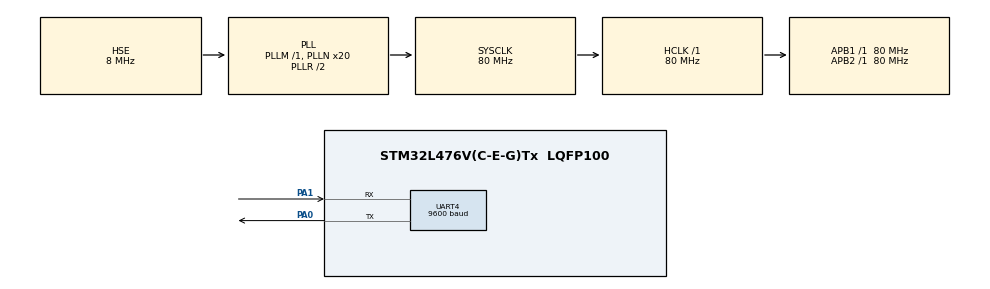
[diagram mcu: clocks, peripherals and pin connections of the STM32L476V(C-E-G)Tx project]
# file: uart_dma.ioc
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Dma.Request0=UART4_RX
Dma.Request1=UART4_TX
Dma.UART4_RX.0.Direction=DMA_PERIPH_TO_MEMORY
Dma.UART4_RX.0.Instance=DMA2_Channel5
Dma.UART4_RX.0.MemDataAlignment=DMA_MDATAALIGN_BYTE
Dma.UART4_RX.0.MemInc=DMA_MINC_ENABLE
Dma.UART4_RX.0.Mode=DMA_NORMAL
Dma.UART4_RX.0.PeriphDataAlignment=DMA_PDATAALIGN_BYTE
Dma.UART4_RX.0.PeriphInc=DMA_PINC_DISABLE
Dma.UART4_RX.0.Priority=DMA_PRIORITY_HIGH
Dma.UART4_TX.1.Direction=DMA_MEMORY_TO_PERIPH
Dma.UART4_TX.1.Instance=DMA2_Channel3
Dma.UART4_TX.1.MemDataAlignment=DMA_MDATAALIGN_BYTE
Dma.UART4_TX.1.MemInc=DMA_MINC_ENABLE
Dma.UART4_TX.1.Mode=DMA_NORMAL
Dma.UART4_TX.1.PeriphDataAlignment=DMA_PDATAALIGN_BYTE
Dma.UART4_TX.1.PeriphInc=DMA_PINC_DISABLE
Dma.UART4_TX.1.Priority=DMA_PRIORITY_LOW
Mcu.Family=STM32L4
Mcu.Name=STM32L476V(C-E-G)Tx
Mcu.Package=LQFP100
NVIC.DMA2_Channel3_IRQn=true\:0\:0\:false\:false\:true\:false\:true
NVIC.DMA2_Channel5_IRQn=true\:0\:0\:false\:false\:true\:false\:true
NVIC.PriorityGroup=NVIC_PRIORITYGROUP_4
NVIC.UART4_IRQn=true\:0\:0\:false\:false\:true\:true\:true
PA0.Mode=Asynchronous
PA0.Signal=UART4_TX
PA1.Mode=Asynchronous
PA1.Signal=UART4_RX
PH0-OSC_IN\ (PH0).Mode=HSE-External-Oscillator
PH0-OSC_IN\ (PH0).Signal=RCC_OSC_IN
PH1-OSC_OUT\ (PH1).Mode=HSE-External-Oscillator
PH1-OSC_OUT\ (PH1).Signal=RCC_OSC_OUT
ProjectManager.HeapSize=0x200
ProjectManager.StackSize=0x400
ProjectManager.TargetToolchain=EWARM V8
RCC.ADCFreq_Value=32000000
RCC.AHBFreq_Value=80000000
RCC.APB1Freq_Value=80000000
RCC.APB1TimFreq_Value=80000000
RCC.APB2Freq_Value=80000000
RCC.APB2TimFreq_Value=80000000
RCC.CortexFreq_Value=80000000
RCC.HCLKFreq_Value=80000000
RCC.HSE_VALUE=8000000
RCC.HSI_VALUE=16000000
RCC.LSE_VALUE=32768
RCC.MSI_VALUE=4000000
RCC.PLLN=20
RCC.PLLSourceVirtual=RCC_PLLSOURCE_HSE
RCC.SYSCLKFreq_VALUE=80000000
RCC.SYSCLKSource=RCC_SYSCLKSOURCE_PLLCLK
RCC.USBFreq_Value=32000000
RCC.VCOOutputFreq_Value=160000000
UART4.BaudRate=9600
board=custom

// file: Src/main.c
/* USER CODE BEGIN Header */
/**
  ******************************************************************************
  * @file           : main.c
  * @brief          : Main program body
  ******************************************************************************
  * @attention
  *
  * <h2><center>&copy; Copyright (c) 2019 STMicroelectronics.
  * All rights reserved.</center></h2>
  *
  * This software component is licensed by ST under BSD 3-Clause license,
  * the "License"; You may not use this file except in compliance with the
  * License. You may obtain a copy of the License at:
  *                        opensource.org/licenses/BSD-3-Clause
  *
  ******************************************************************************
  */
/* USER CODE END Header */

#include "main.h"

UART_HandleTypeDef huart4;
DMA_HandleTypeDef hdma_uart4_rx;
DMA_HandleTypeDef hdma_uart4_tx;

/* USER CODE BEGIN PV */
uint8_t rx_buff[8];
/* USER CODE END PV */

void SystemClock_Config(void);
static void MX_GPIO_Init(void);
static void MX_DMA_Init(void);
static void MX_UART4_Init(void);

int main(void)
{

  /* MCU Configuration--------------------------------------------------------*/

  /* Reset of all peripherals, Initializes the Flash interface and the Systick. */
  HAL_Init();

  /* Configure the system clock */
  SystemClock_Config();

  /* Initialize all configured peripherals */
  MX_GPIO_Init();
  MX_DMA_Init();
  MX_UART4_Init();
  /* USER CODE BEGIN 2 */
  if (HAL_UART_Transmit_DMA(&huart4, "hello123", 8) != HAL_OK)
  {
    Error_Handler();
  }

  if (HAL_UART_Receive_DMA(&huart4, rx_buff, 8) != HAL_OK)
  {
    Error_Handler();
  }
  /* USER CODE END 2 */

  /* Infinite loop */
  /* USER CODE BEGIN WHILE */
  while (1)
  {
    if (HAL_UART_Transmit_DMA(&huart4, "hello123", 8) != HAL_OK)
    {
      Error_Handler();
    }
    HAL_Delay(1000);
    /* USER CODE END WHILE */

  }
}

void SystemClock_Config(void)
{
  RCC_OscInitTypeDef RCC_OscInitStruct = {0};
  RCC_ClkInitTypeDef RCC_ClkInitStruct = {0};
  RCC_PeriphCLKInitTypeDef PeriphClkInit = {0};

  /** Initializes the CPU, AHB and APB busses clocks
  */
  RCC_OscInitStruct.OscillatorType = RCC_OSCILLATORTYPE_HSE;
  RCC_OscInitStruct.HSEState = RCC_HSE_ON;
  RCC_OscInitStruct.PLL.PLLState = RCC_PLL_ON;
  RCC_OscInitStruct.PLL.PLLSource = RCC_PLLSOURCE_HSE;
  RCC_OscInitStruct.PLL.PLLM = 1;
  RCC_OscInitStruct.PLL.PLLN = 20;
  RCC_OscInitStruct.PLL.PLLP = RCC_PLLP_DIV7;
  RCC_OscInitStruct.PLL.PLLQ = RCC_PLLQ_DIV2;
  RCC_OscInitStruct.PLL.PLLR = RCC_PLLR_DIV2;
  if (HAL_RCC_OscConfig(&RCC_OscInitStruct) != HAL_OK)
  {
    Error_Handler();
  }
  /** Initializes the CPU, AHB and APB busses clocks
  */
  RCC_ClkInitStruct.ClockType = RCC_CLOCKTYPE_HCLK|RCC_CLOCKTYPE_SYSCLK
                              |RCC_CLOCKTYPE_PCLK1|RCC_CLOCKTYPE_PCLK2;
  RCC_ClkInitStruct.SYSCLKSource = RCC_SYSCLKSOURCE_PLLCLK;
  RCC_ClkInitStruct.AHBCLKDivider = RCC_SYSCLK_DIV1;
  RCC_ClkInitStruct.APB1CLKDivider = RCC_HCLK_DIV1;
  RCC_ClkInitStruct.APB2CLKDivider = RCC_HCLK_DIV1;

  if (HAL_RCC_ClockConfig(&RCC_ClkInitStruct, FLASH_LATENCY_4) != HAL_OK)
  {
    Error_Handler();
  }
  PeriphClkInit.PeriphClockSelection = RCC_PERIPHCLK_UART4;
  PeriphClkInit.Uart4ClockSelection = RCC_UART4CLKSOURCE_PCLK1;
  if (HAL_RCCEx_PeriphCLKConfig(&PeriphClkInit) != HAL_OK)
  {
    Error_Handler();
  }
  /** Configure the main internal regulator output voltage
  */
  if (HAL_PWREx_ControlVoltageScaling(PWR_REGULATOR_VOLTAGE_SCALE1) != HAL_OK)
  {
    Error_Handler();
  }
}

static void MX_UART4_Init(void)
{

  huart4.Instance = UART4;
  huart4.Init.BaudRate = 9600;
  huart4.Init.WordLength = UART_WORDLENGTH_8B;
  huart4.Init.StopBits = UART_STOPBITS_1;
  huart4.Init.Parity = UART_PARITY_NONE;
  huart4.Init.Mode = UART_MODE_TX_RX;
  huart4.Init.HwFlowCtl = UART_HWCONTROL_NONE;
  huart4.Init.OverSampling = UART_OVERSAMPLING_16;
  huart4.Init.OneBitSampling = UART_ONE_BIT_SAMPLE_DISABLE;
  huart4.AdvancedInit.AdvFeatureInit = UART_ADVFEATURE_NO_INIT;
  if (HAL_UART_Init(&huart4) != HAL_OK)
  {
    Error_Handler();
  }

}

static void MX_DMA_Init(void)
{

  /* DMA controller clock enable */
  __HAL_RCC_DMA2_CLK_ENABLE();

  /* DMA interrupt init */
  /* DMA2_Channel3_IRQn interrupt configuration */
  HAL_NVIC_SetPriority(DMA2_Channel3_IRQn, 0, 0);
  HAL_NVIC_EnableIRQ(DMA2_Channel3_IRQn);
  /* DMA2_Channel5_IRQn interrupt configuration */
  HAL_NVIC_SetPriority(DMA2_Channel5_IRQn, 0, 0);
  HAL_NVIC_EnableIRQ(DMA2_Channel5_IRQn);

}

static void MX_GPIO_Init(void)
{

  /* GPIO Ports Clock Enable */
  __HAL_RCC_GPIOH_CLK_ENABLE();
  __HAL_RCC_GPIOA_CLK_ENABLE();

}

/* USER CODE BEGIN 4 */
void HAL_UART_RxCpltCallback(UART_HandleTypeDef *huart)
{
  printf("Rx buffer is full!\n");
}

void DMA2_Channel5_IRQHandler(void)
{
  /* USER CODE BEGIN DMA2_Channel5_IRQn 0 */

  /* USER CODE END DMA2_Channel5_IRQn 0 */
  HAL_DMA_IRQHandler(&hdma_uart4_rx);
  /* USER CODE BEGIN DMA2_Channel5_IRQn 1 */
  HAL_UART_Receive_DMA(&huart4, rx_buff, 8);
  /* USER CODE END DMA2_Channel5_IRQn 1 */
}

void UART4_IRQHandler(void)
{
  /* USER CODE BEGIN UART4_IRQn 0 */

  /* USER CODE END UART4_IRQn 0 */
  HAL_UART_IRQHandler(&huart4);
  /* USER CODE BEGIN UART4_IRQn 1 */
  HAL_UART_Receive_DMA(&huart4, rx_buff, 8);
  /* USER CODE END UART4_IRQn 1 */
}

/* USER CODE END 4 */

void Error_Handler(void)
{
}

/************************ (C) COPYRIGHT STMicroelectronics *****END OF FILE****/
